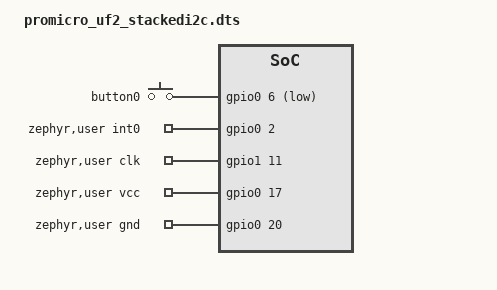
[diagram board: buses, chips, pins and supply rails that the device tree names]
// Copyright (c) 2024 Nordic Semiconductor ASA
// SPDX-License-Identifier: Apache-2.0

/dts-v1/;
#include "promicro_uf2.dts"

&pinctrl {
	i2c0_default: i2c0_default {
		/delete-node/ group1;
		group1 {
			psels = <NRF_PSEL(TWIM_SDA, 0, 24)>, <NRF_PSEL(TWIM_SCL, 0, 22)>;
			bias-disable;
		};
	};

	i2c0_sleep: i2c0_sleep {
		/delete-node/ group1;
		group1 {
			psels = <NRF_PSEL(TWIM_SDA, 0, 24)>, <NRF_PSEL(TWIM_SCL, 0, 22)>;
			bias-disable;
			low-power-enable;
		};
	};
};

/ {
	buttons {
		/delete-node/ button0;
		button0: button_0 {
			gpios = <&gpio0 6 (GPIO_PULL_UP | GPIO_ACTIVE_LOW)>;
		};
	};

	aliases {
		sw0 = &button0;
	};

	zephyr,user {
		/delete-property/ int0-gpios;
		/delete-property/ vcc-gpios;
		int0-gpios = <&gpio0 2 0>;
		clk-gpios = <&gpio1 11 GPIO_OPEN_DRAIN>;
		vcc-gpios = <&gpio0 17 GPIO_OPEN_SOURCE>;
		gnd-gpios = <&gpio0 20 GPIO_OPEN_DRAIN>;
	};
};

/delete-node/ &spi3;
